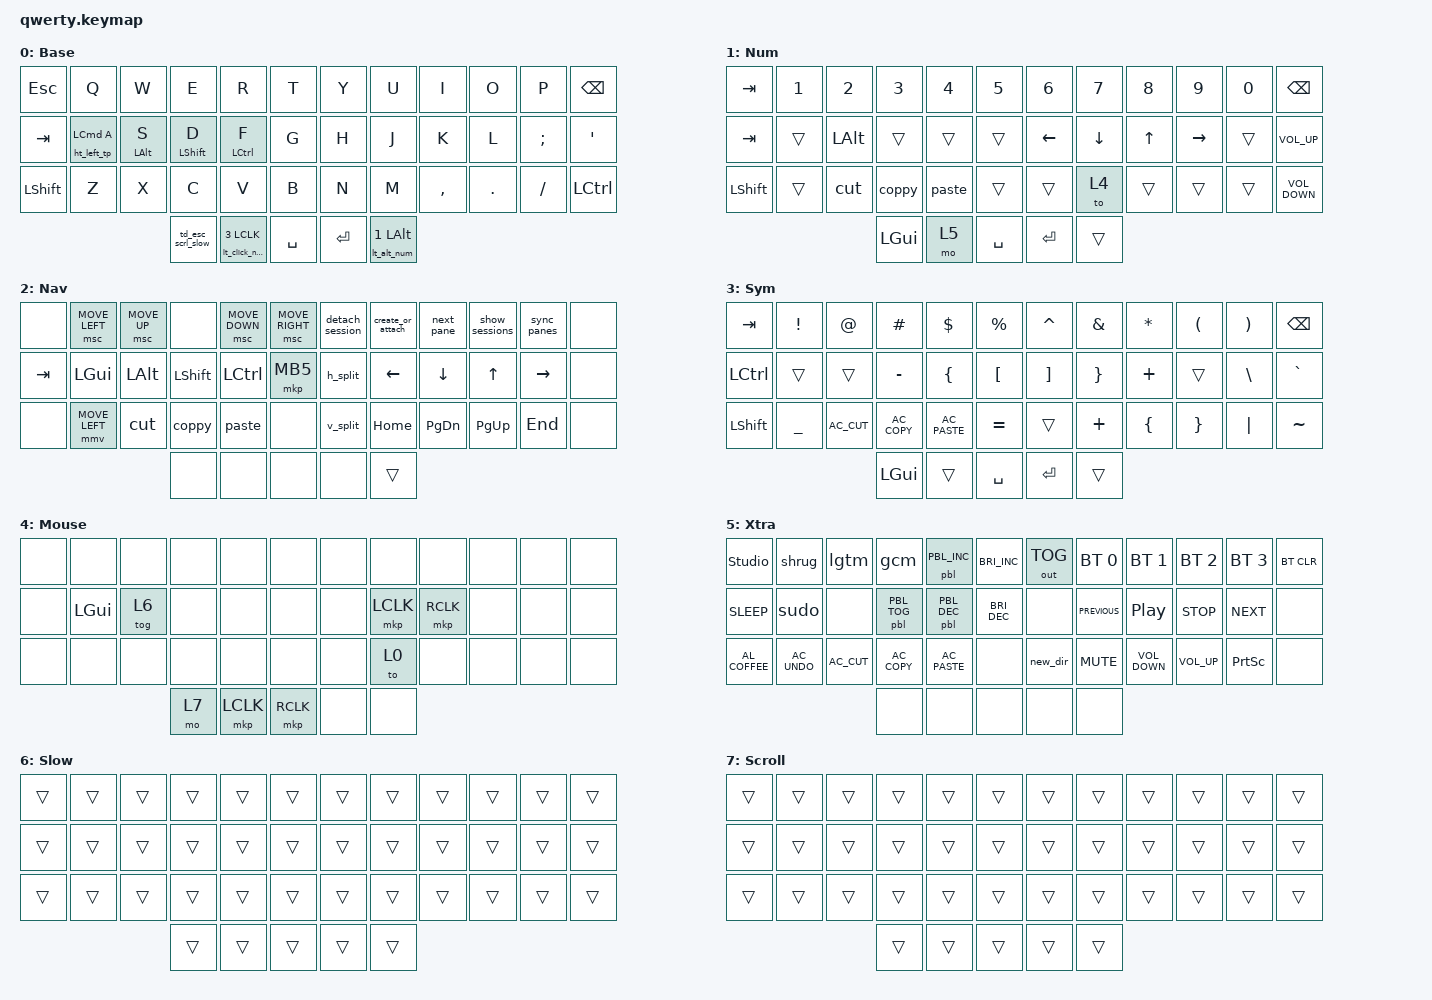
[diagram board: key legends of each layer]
/* upstream bindings and behaviors */
#include <behaviors.dtsi>
#include <dt-bindings/zmk/bt.h>
#include <dt-bindings/zmk/keys.h>
#include <dt-bindings/zmk/mouse.h>
#include <dt-bindings/zmk/outputs.h>
#include <behaviors/mouse_keys.dtsi>
#include <dt-bindings/zmk/ext_power.h>

/* local overlays */
#include "keymap_features/prospector_brightness.dtsi"
#include "keymap_features/macros.dtsi"
#include "keymap_features/behaviors.dtsi"
#include "keymap_features/combos.dtsi"

/ {
/* --- KEYMAP CONFIG --- */
// ╭──────┬──────┬──────┬──────┬──────┬──────╮  ╭──────┬──────┬──────┬──────┬──────┬──────╮
//    00     01     02     03    04      05        06     07     08     09     10     11
// ├──────┼──────┼──────┼──────┼──────┼──────┤  ├──────┼──────┼──────┼──────┼──────┼──────┤
//    12     13     14     15    16      17        18     19     20     21     22     23
// ├──────┼──────┼──────┼──────┼──────┼──────┤  ├──────┼──────┼──────┼──────┼──────┼──────┤
//    24     25     26     27    28      29        30     31     32     33     34     35
// ╰──────┴──────┴──────┼──────┼──────┼──────┤  ├──────┼──────┼──────┴──────┴──────┴──────╯
//                         36     37     38        39     40
//                      ╰──────┴──────┴──────╯  ╰──────┴──────╯
// #define BASE    0
// #define NUM     1
// #define NAV     2
// #define SYM     3
// #define GAME    4
// #define EXTRAS  5
// #define SLOW    6
// #define SCROLL  7

// This shared keymap builds for prospector and non-prospector firmwares. 
// This stubs the key bindings that are contained in the prospector module
// so non-prospector firmware can build.
#ifndef CONFIG_SHIELD_PROSPECTOR_ADAPTER
    behaviors {
        /omit-if-no-ref/ pbl: prospector_brightness_stub {
            compatible = "zmk,behavior-macro-two-param";
            #binding-cells = <2>;
            bindings = <&none>;
        };
    };
#endif

    keymap {
        compatible = "zmk,keymap";
        BASE {
            display-name = "Base";
            bindings = <
// ╭───────────────┬────────────────┬────────────────┬─────────────────┬─────────────────┬──────╮  ╭──────┬──────────────────┬──────────────────┬─────────────────┬─────────────────┬─────────────╮
    &kp ESC              &kp Q            &kp W            &kp E             &kp R             &kp T    &kp Y   &kp U              &kp I              &kp O             &kp P           &kp BSPC
// ├───────────────┼────────────────┼────────────────┼─────────────────┼─────────────────┼──────┤  ├──────┼──────────────────┼──────────────────┼─────────────────┼─────────────────┼─────────────┤
    &kp TAB          &ht_left_tp LCMD A  &ht_left LALT S  &ht_left LSHFT D  &ht_left LCTRL F  &kp G    &kp H   &kp J            &kp K               &kp L           &kp SEMICOLON       &kp SQT
// ├───────────────┼────────────────┼────────────────┼─────────────────┼─────────────────┼──────┤  ├──────┼──────────────────┼──────────────────┼─────────────────┼─────────────────┼─────────────┤
    &kp LSHIFT         &kp Z            &kp X            &kp C             &kp V             &kp B    &kp N   &kp M              &kp COMMA           &kp DOT        &kp FSLH          &kp LCTRL
// ╰───────────────┴────────────────┴────────────────┼─────────────────┼─────────────────┼──────┤  ├──────┼──────────────────┼──────────────────┴─────────────────┴─────────────────┴─────────────╯
                                                &td_esc_scrl_slow  &lt_click_num 3 LCLK &kp SPACE   &kp ENTER    &lt_alt_num 1 LALT
                                                         // ╰──────────────────┴─────────┴──────╯  ╰──────────┴──────────────╯
            >;
        };

        NUM {
            display-name = "Num";
            bindings = <
        &kp TAB    &kp N1  &kp N2        &kp N3         &kp N4          &kp N5   &kp N6          &kp N7    &kp N8  &kp N9           &kp N0  &kp BSPC
        &kp TAB    &trans  &kp LEFT_ALT  &trans         &trans          &trans   &kp LEFT_ARROW  &kp DOWN  &kp UP  &kp RIGHT_ARROW  &trans  &kp C_VOLUME_UP
        &kp LSHFT  &trans  &cut          &coppy         &paste          &trans   &trans          &to 4    &trans  &trans           &trans  &kp C_VOLUME_DOWN
                                        &kp LGUI         &mo 5          &kp SPACE    &kp RET       &trans
            >;
        };

        NAV {
            display-name = "Nav";
            bindings = <
        &none    &msc MOVE_LEFT  &msc MOVE_UP    &none        &msc MOVE_DOWN  &msc MOVE_RIGHT     &detach_session  &create_or_attach  &next_pane   &show_sessions  &sync_panes       &none
        &kp TAB  &kp LGUI        &kp LALT        &kp LSHFT    &kp LCTRL       &mkp MB5            &h_split         &kp LEFT_ARROW     &kp DOWN     &kp UP          &kp RIGHT_ARROW   &none
        &none    &mmv MOVE_LEFT  &cut            &coppy       &paste          &none               &v_split         &kp HOME           &kp PG_DN    &kp PG_UP       &kp END           &none
                                                            &none   &none   &none               &none   &trans
            >;
        };

        SYM {
            display-name = "Sym";
            bindings = <
        &kp TAB    &kp EXCL   &kp AT        &kp HASH      &kp DLLR       &kp PRCNT      &kp CARET  &kp AMPS  &kp ASTRK  &kp LPAR  &kp RPAR  &kp BSPC
        &kp LCTRL  &trans     &trans        &kp MINUS     &kp LBRC       &kp LBKT       &kp RBKT   &kp RBRC  &kp PLUS   &trans    &kp BSLH  &kp GRAVE
        &kp LSHFT  &kp UNDER  &kp C_AC_CUT  &kp C_AC_COPY &kp C_AC_PASTE &kp EQUAL      &trans     &kp PLUS  &kp LBRC   &kp RBRC  &kp PIPE  &kp TILDE
                                            &kp LGUI      &trans         &kp SPACE      &kp RET    &trans
            >;
        };

        GAME {
            display-name = "Mouse";
            bindings = <
        &none  &none     &none    &none  &none  &none     &none  &none    &none  &none  &none  &none
        &none  &kp LGUI  &tog 6   &none  &none  &none     &none  &mkp LCLK  &mkp RCLK  &none  &none  &none
        &none  &none     &none    &none  &none  &none     &none  &to 0    &none  &none  &none  &none
                            &mo 7  &mkp LCLK  &mkp RCLK     &none  &none
            >;
        };

        EXTRAS {
            display-name = "Xtra";
            bindings = <
&studio_unlock    &shrug          &lgtm           &gcm            &pbl PBL_INC    &kp C_BRIGHTNESS_INC    &out OUT_TOG  &bt BT_SEL 0    &bt BT_SEL 1       &bt BT_SEL 2      &bt BT_SEL 3     &bt BT_CLR
&kp C_SLEEP       &sudo           &none           &pbl PBL_TOG    &pbl PBL_DEC    &kp C_BRIGHTNESS_DEC    &none         &kp C_PREVIOUS  &kp C_PLAY_PAUSE   &kp C_STOP        &kp C_NEXT       &none
&kp C_AL_COFFEE   &kp C_AC_UNDO   &kp C_AC_CUT    &kp C_AC_COPY   &kp C_AC_PASTE  &none                   &new_dir      &kp K_MUTE      &kp C_VOLUME_DOWN  &kp C_VOLUME_UP   &kp PRINTSCREEN  &none
                                                                                   &none  &none  &none    &none         &none
            >;
        };

        SLOW {
            display-name = "Slow";
            bindings = <
// ╭────────┬────────┬────────┬────────┬────────┬────────╮  ╭────────┬────────┬────────┬────────┬────────┬────────╮
    &trans    &trans   &trans   &trans   &trans   &trans      &trans   &trans   &trans   &trans   &trans   &trans
// ├────────┼────────┼────────┼────────┼────────┼────────┤  ├────────┼────────┼────────┼────────┼────────┼────────┤
    &trans    &trans   &trans   &trans   &trans   &trans      &trans   &trans   &trans   &trans   &trans   &trans
// ├────────┼────────┼────────┼────────┼────────┼────────┤  ├────────┼────────┼────────┼────────┼────────┼────────┤
    &trans    &trans   &trans   &trans   &trans   &trans      &trans   &trans   &trans   &trans   &trans   &trans
// ╰────────┴────────┴────────┼────────┼────────┼────────┤  ├────────┼────────┼────────┴────────┴────────┴────────╯
                                  &trans   &trans   &trans      &trans   &trans
                             // ╰────────┴────────┴────────╯  ╰────────┴────────╯
            >;
        };

        SCROLL {
            display-name = "Scroll";
            bindings = <
// ╭────────┬────────┬────────┬────────┬────────┬────────╮  ╭────────┬────────┬────────┬────────┬────────┬────────╮
    &trans    &trans   &trans   &trans   &trans   &trans      &trans   &trans   &trans   &trans   &trans   &trans
// ├────────┼────────┼────────┼────────┼────────┼────────┤  ├────────┼────────┼────────┼────────┼────────┼────────┤
    &trans    &trans   &trans   &trans   &trans   &trans      &trans   &trans   &trans   &trans   &trans   &trans
// ├────────┼────────┼────────┼────────┼────────┼────────┤  ├────────┼────────┼────────┼────────┼────────┼────────┤
    &trans    &trans   &trans   &trans   &trans   &trans      &trans   &trans   &trans   &trans   &trans   &trans
// ╰────────┴────────┴────────┼────────┼────────┼────────┤  ├────────┼────────┼────────┴────────┴────────┴────────╯
                                  &trans   &trans   &trans      &trans   &trans
                             // ╰────────┴────────┴────────╯  ╰────────┴────────╯
            >;
        };
    };
};
